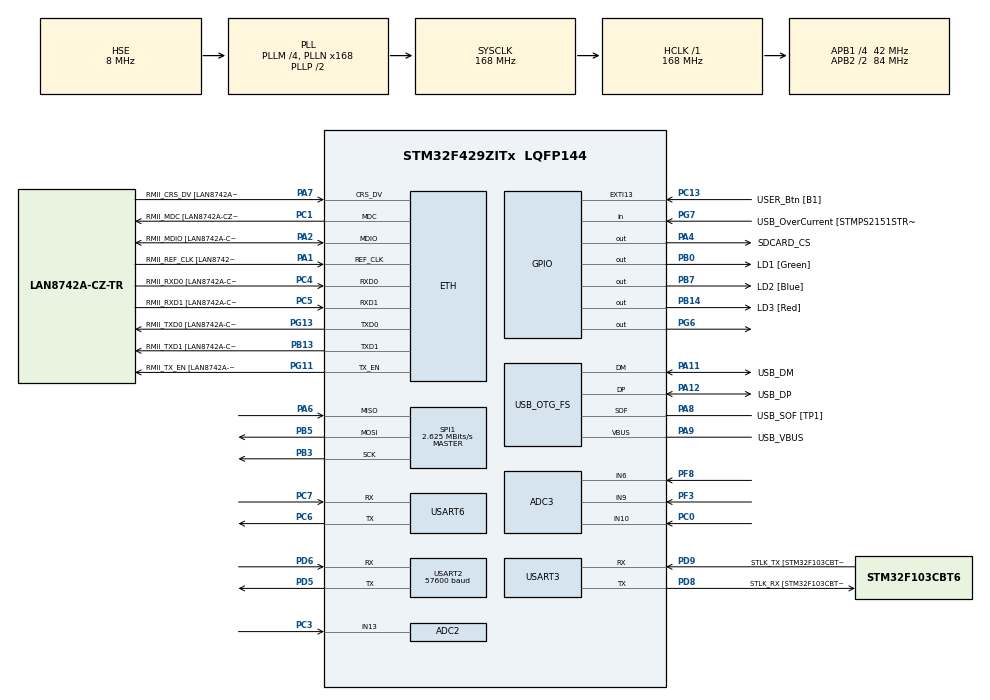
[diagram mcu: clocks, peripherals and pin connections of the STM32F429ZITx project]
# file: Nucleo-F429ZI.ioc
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ADC2.Channel-0\#ChannelRegularConversion=ADC_CHANNEL_13
ADC2.ContinuousConvMode=ENABLE
ADC2.NbrOfConversionFlag=1
ADC2.Rank-0\#ChannelRegularConversion=1
ADC2.SamplingTime-0\#ChannelRegularConversion=ADC_SAMPLETIME_3CYCLES
ADC3.Channel-0\#ChannelRegularConversion=ADC_CHANNEL_6
ADC3.ContinuousConvMode=ENABLE
ADC3.NbrOfConversionFlag=1
ADC3.Rank-0\#ChannelRegularConversion=1
ADC3.SamplingTime-0\#ChannelRegularConversion=ADC_SAMPLETIME_3CYCLES
Dma.Request0=USART2_RX
Dma.Request1=USART2_TX
Dma.Request2=USART3_RX
Dma.Request3=USART3_TX
Dma.USART2_RX.0.Direction=DMA_PERIPH_TO_MEMORY
Dma.USART2_RX.0.FIFOMode=DMA_FIFOMODE_DISABLE
Dma.USART2_RX.0.Instance=DMA1_Stream5
Dma.USART2_RX.0.MemDataAlignment=DMA_MDATAALIGN_BYTE
Dma.USART2_RX.0.MemInc=DMA_MINC_ENABLE
Dma.USART2_RX.0.Mode=DMA_NORMAL
Dma.USART2_RX.0.PeriphDataAlignment=DMA_PDATAALIGN_BYTE
Dma.USART2_RX.0.PeriphInc=DMA_PINC_DISABLE
Dma.USART2_RX.0.Priority=DMA_PRIORITY_LOW
Dma.USART2_TX.1.Direction=DMA_MEMORY_TO_PERIPH
Dma.USART2_TX.1.FIFOMode=DMA_FIFOMODE_DISABLE
Dma.USART2_TX.1.Instance=DMA1_Stream6
Dma.USART2_TX.1.MemDataAlignment=DMA_MDATAALIGN_BYTE
Dma.USART2_TX.1.MemInc=DMA_MINC_ENABLE
Dma.USART2_TX.1.Mode=DMA_CIRCULAR
Dma.USART2_TX.1.PeriphDataAlignment=DMA_PDATAALIGN_BYTE
Dma.USART2_TX.1.PeriphInc=DMA_PINC_DISABLE
Dma.USART2_TX.1.Priority=DMA_PRIORITY_LOW
Dma.USART3_RX.2.Direction=DMA_PERIPH_TO_MEMORY
Dma.USART3_RX.2.FIFOMode=DMA_FIFOMODE_DISABLE
Dma.USART3_RX.2.Instance=DMA1_Stream1
Dma.USART3_RX.2.MemDataAlignment=DMA_MDATAALIGN_BYTE
Dma.USART3_RX.2.MemInc=DMA_MINC_ENABLE
Dma.USART3_RX.2.Mode=DMA_CIRCULAR
Dma.USART3_RX.2.PeriphDataAlignment=DMA_PDATAALIGN_BYTE
Dma.USART3_RX.2.PeriphInc=DMA_PINC_DISABLE
Dma.USART3_RX.2.Priority=DMA_PRIORITY_LOW
Dma.USART3_TX.3.Direction=DMA_MEMORY_TO_PERIPH
Dma.USART3_TX.3.FIFOMode=DMA_FIFOMODE_DISABLE
Dma.USART3_TX.3.Instance=DMA1_Stream3
Dma.USART3_TX.3.MemDataAlignment=DMA_MDATAALIGN_BYTE
Dma.USART3_TX.3.MemInc=DMA_MINC_ENABLE
Dma.USART3_TX.3.Mode=DMA_NORMAL
Dma.USART3_TX.3.PeriphDataAlignment=DMA_PDATAALIGN_BYTE
Dma.USART3_TX.3.PeriphInc=DMA_PINC_DISABLE
Dma.USART3_TX.3.Priority=DMA_PRIORITY_LOW
ETH.MediaInterface=HAL_ETH_RMII_MODE
ETH.PHY_Name=LAN8742A_PHY_ADDRESS
ETH.PHY_Value=0
ETH.PhyAddress=0
FATFS._MAX_SS=4096
FATFS._USE_LFN=1
Mcu.Family=STM32F4
Mcu.Name=STM32F429ZITx
Mcu.Package=LQFP144
NVIC.ADC_IRQn=true\:6\:0\:true\:false\:true\:true\:true\:true
NVIC.DMA1_Stream1_IRQn=true\:0\:0\:false\:false\:true\:false\:true\:true
NVIC.DMA1_Stream3_IRQn=true\:0\:0\:false\:false\:true\:false\:true\:true
NVIC.DMA1_Stream5_IRQn=true\:0\:0\:false\:false\:true\:false\:true\:true
NVIC.DMA1_Stream6_IRQn=true\:0\:0\:false\:false\:true\:false\:true\:true
NVIC.PriorityGroup=NVIC_PRIORITYGROUP_4
NVIC.TIM1_UP_TIM10_IRQn=true\:15\:0\:true\:false\:true\:false\:true\:true
NVIC.TimeBase=TIM1_UP_TIM10_IRQn
NVIC.TimeBaseIP=TIM1
NVIC.USART2_IRQn=true\:5\:0\:true\:false\:true\:true\:true\:true
NVIC.USART3_IRQn=true\:5\:0\:true\:false\:true\:true\:true\:true
NVIC.USART6_IRQn=true\:5\:0\:true\:false\:true\:true\:true\:true
PA1.GPIO_Label=RMII_REF_CLK [LAN8742A-CZ-TR_REFCLK0]
PA1.Mode=RMII
PA1.Signal=ETH_REF_CLK
PA10.GPIO_Label=USB_ID
PA10.Signal=USB_OTG_FS_ID
PA11.GPIO_Label=USB_DM
PA11.Mode=Device_Only
PA11.Signal=USB_OTG_FS_DM
PA12.GPIO_Label=USB_DP
PA12.Mode=Device_Only
PA12.Signal=USB_OTG_FS_DP
PA13.GPIO_Label=TMS
PA13.Mode=Serial_Wire
PA13.Signal=SYS_JTMS-SWDIO
PA14.GPIO_Label=TCK
PA14.Mode=Serial_Wire
PA14.Signal=SYS_JTCK-SWCLK
PA2.GPIO_Label=RMII_MDIO [LAN8742A-CZ-TR_MDIO]
PA2.Mode=RMII
PA2.Signal=ETH_MDIO
PA4.GPIO_Label=SDCARD_CS
PA4.PinState=GPIO_PIN_SET
PA4.Signal=GPIO_Output
PA6.Mode=Full_Duplex_Master
PA6.Signal=SPI1_MISO
PA7.GPIO_Label=RMII_CRS_DV [LAN8742A-CZ-TR_CRS_DV]
PA7.Mode=RMII
PA7.Signal=ETH_CRS_DV
PA8.GPIO_Label=USB_SOF [TP1]
PA8.Mode=Activate_SOF_FS
PA8.Signal=USB_OTG_FS_SOF
PA9.GPIO_Label=USB_VBUS
PA9.Mode=Activate_VBUS
PA9.Signal=USB_OTG_FS_VBUS
PB0.GPIO_Label=LD1 [Green]
PB0.Signal=GPIO_Output
PB13.GPIO_Label=RMII_TXD1 [LAN8742A-CZ-TR_TXD1]
PB13.Mode=RMII
PB13.Signal=ETH_TXD1
PB14.GPIO_Label=LD3 [Red]
PB14.Signal=GPIO_Output
PB3.Mode=Full_Duplex_Master
PB3.Signal=SPI1_SCK
PB5.Mode=Full_Duplex_Master
PB5.Signal=SPI1_MOSI
PB7.GPIO_Label=LD2 [Blue]
PB7.Signal=GPIO_Output
PC0.Signal=ADCx_IN10
PC1.GPIO_Label=RMII_MDC [LAN8742A-CZ-TR_MDC]
PC1.Mode=RMII
PC1.Signal=ETH_MDC
PC13.GPIO_Label=USER_Btn [B1]
PC13.Signal=GPXTI13
PC14/OSC32_IN.Mode=LSE-External-Oscillator
PC14/OSC32_IN.Signal=RCC_OSC32_IN
PC15/OSC32_OUT.Mode=LSE-External-Oscillator
PC15/OSC32_OUT.Signal=RCC_OSC32_OUT
PC3.Signal=ADCx_IN13
PC4.GPIO_Label=RMII_RXD0 [LAN8742A-CZ-TR_RXD0]
PC4.Mode=RMII
PC4.Signal=ETH_RXD0
PC5.GPIO_Label=RMII_RXD1 [LAN8742A-CZ-TR_RXD1]
PC5.Mode=RMII
PC5.Signal=ETH_RXD1
PC6.Mode=Asynchronous
PC6.Signal=USART6_TX
PC7.Mode=Asynchronous
PC7.Signal=USART6_RX
PD5.Mode=Asynchronous
PD5.Signal=USART2_TX
PD6.Mode=Asynchronous
PD6.Signal=USART2_RX
PD8.GPIO_Label=STLK_RX [STM32F103CBT6_PA3]
PD8.Mode=Asynchronous
PD8.Signal=USART3_TX
PD9.GPIO_Label=STLK_TX [STM32F103CBT6_PA2]
PD9.Mode=Asynchronous
PD9.Signal=USART3_RX
PF3.Mode=IN9
PF3.Signal=ADC3_IN9
PF8.Mode=IN6
PF8.Signal=ADC3_IN6
PG11.GPIO_Label=RMII_TX_EN [LAN8742A-CZ-TR_TXEN]
PG11.Mode=RMII
PG11.Signal=ETH_TX_EN
PG13.GPIO_Label=RMII_TXD0 [LAN8742A-CZ-TR_TXD0]
PG13.Mode=RMII
PG13.Signal=ETH_TXD0
PG6.Signal=GPIO_Output
PG7.GPIO_Label=USB_OverCurrent [STMPS2151STR_FAULT]
PG7.Signal=GPIO_Input
PH0/OSC_IN.GPIO_Label=MCO [STM32F103CBT6_PA8]
PH0/OSC_IN.Mode=HSE-External-Clock-Source
PH0/OSC_IN.Signal=RCC_OSC_IN
PH1/OSC_OUT.Mode=HSE-External-Clock-Source
PH1/OSC_OUT.Signal=RCC_OSC_OUT
ProjectManager.HeapSize=0x200
ProjectManager.StackSize=0x400
ProjectManager.TargetToolchain=Makefile
RCC.48MHZClocksFreq_Value=48000000
RCC.AHBFreq_Value=168000000
RCC.APB1CLKDivider=RCC_HCLK_DIV4
RCC.APB1Freq_Value=42000000
RCC.APB1TimFreq_Value=84000000
RCC.APB2CLKDivider=RCC_HCLK_DIV2
RCC.APB2Freq_Value=84000000
RCC.APB2TimCLKDivider=2
RCC.APB2TimFreq_Value=168000000
RCC.CortexFreq_Value=168000000
RCC.HCLKFreq_Value=168000000
RCC.HSE_VALUE=8000000
RCC.HSI_VALUE=16000000
RCC.PLLM=4
RCC.PLLMUL=RCC_PLL_MUL9
RCC.PLLN=168
RCC.PLLQ=7
RCC.PRESCALERUSB=RCC_USBCLKSOURCE_PLL_DIV1_5
RCC.SYSCLKFreq_VALUE=168000000
RCC.SYSCLKSource=RCC_SYSCLKSOURCE_PLLCLK
RCC.SYSCLKSourceVirtual=RCC_SYSCLKSOURCE_PLLCLK
RCC.USBFreq_Value=48000000
RCC.VCOOutputFreq_Value=336000000
SH.ADCx_IN10.0=ADC3_IN10,IN10
SH.ADCx_IN13.0=ADC2_IN13,IN13
SPI1.BaudRatePrescaler=SPI_BAUDRATEPRESCALER_32
SPI1.CalculateBaudRate=2.625 MBits/s
SPI1.Direction=SPI_DIRECTION_2LINES
SPI1.Mode=SPI_MODE_MASTER
SPI1.VirtualType=VM_MASTER
USART2.BaudRate=57600
USART2.VirtualMode=VM_ASYNC
USART3.VirtualMode=VM_ASYNC
USART6.VirtualMode=VM_ASYNC
USB_OTG_FS.VirtualMode=Device_Only
VP_FATFS_VS_Generic.Mode=User_defined
VP_SYS_VS_tim1.Mode=TIM1
board=NUCLEO-F429ZI

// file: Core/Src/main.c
/* USER CODE BEGIN Header */
/**
  ******************************************************************************
  * @file           : main.c
  * @brief          : Main program body
  ******************************************************************************
  * @attention
  *
  * Copyright (c) 2024 STMicroelectronics.
  * All rights reserved.
  *
  * This software is licensed under terms that can be found in the LICENSE file
  * in the root directory of this software component.
  * If no LICENSE file comes with this software, it is provided AS-IS.
  *
  ******************************************************************************
  */
/* USER CODE END Header */
#include "main.h"
#include "string.h"
#include "fatfs.h"

/* USER CODE BEGIN Includes */
#include "port_layer.h"
/* USER CODE END Includes */

ETH_TxPacketConfig TxConfig;
ETH_DMADescTypeDef  DMARxDscrTab[ETH_RX_DESC_CNT]; /* Ethernet Rx DMA Descriptors */
ETH_DMADescTypeDef  DMATxDscrTab[ETH_TX_DESC_CNT]; /* Ethernet Tx DMA Descriptors */

ADC_HandleTypeDef hadc2;
ADC_HandleTypeDef hadc3;

ETH_HandleTypeDef heth;

SPI_HandleTypeDef hspi1;

UART_HandleTypeDef huart2;
UART_HandleTypeDef huart3;
UART_HandleTypeDef huart6;
DMA_HandleTypeDef hdma_usart2_rx;
DMA_HandleTypeDef hdma_usart2_tx;
DMA_HandleTypeDef hdma_usart3_rx;
DMA_HandleTypeDef hdma_usart3_tx;

PCD_HandleTypeDef hpcd_USB_OTG_FS;

void SystemClock_Config(void);
static void MX_GPIO_Init(void);
static void MX_DMA_Init(void);
static void MX_ETH_Init(void);
static void MX_SPI1_Init(void);
static void MX_USART2_UART_Init(void);
static void MX_USART3_UART_Init(void);
static void MX_USB_OTG_FS_PCD_Init(void);
static void MX_USART6_UART_Init(void);
static void MX_ADC2_Init(void);
static void MX_ADC3_Init(void);

/* USER CODE BEGIN 0 */
uint8_t n_bytes = 0;
uint8_t rx_buf[16];
/* USER CODE END 0 */

int main(void)
{

  /* MCU Configuration--------------------------------------------------------*/

  /* Reset of all peripherals, Initializes the Flash interface and the Systick. */
  HAL_Init();

  /* Configure the system clock */
  SystemClock_Config();

  /* Initialize all configured peripherals */
  MX_GPIO_Init();
  MX_DMA_Init();
  MX_ETH_Init();
  MX_SPI1_Init();
  MX_USART2_UART_Init();
  MX_USART3_UART_Init();
  MX_USB_OTG_FS_PCD_Init();
  MX_FATFS_Init();
  MX_USART6_UART_Init();
  MX_ADC2_Init();
  MX_ADC3_Init();
  /* USER CODE BEGIN 2 */
  if (port_init()) {
    HAL_UART_Transmit(&debug_uart, (uint8_t *) "Port init successful\r\n", 22, HAL_MAX_DELAY);
  } else {
    HAL_UART_Transmit(&debug_uart, (uint8_t *) "Port init failed\r\n", 18, HAL_MAX_DELAY);
  }
  port_start();
  /* USER CODE END 2 */

  /* Infinite loop */
  while (1)
  {

  }
}

void SystemClock_Config(void)
{
  RCC_OscInitTypeDef RCC_OscInitStruct = {0};
  RCC_ClkInitTypeDef RCC_ClkInitStruct = {0};

  /** Configure the main internal regulator output voltage
  */
  __HAL_RCC_PWR_CLK_ENABLE();
  __HAL_PWR_VOLTAGESCALING_CONFIG(PWR_REGULATOR_VOLTAGE_SCALE1);

  /** Initializes the RCC Oscillators according to the specified parameters
  * in the RCC_OscInitTypeDef structure.
  */
  RCC_OscInitStruct.OscillatorType = RCC_OSCILLATORTYPE_HSE;
  RCC_OscInitStruct.HSEState = RCC_HSE_BYPASS;
  RCC_OscInitStruct.PLL.PLLState = RCC_PLL_ON;
  RCC_OscInitStruct.PLL.PLLSource = RCC_PLLSOURCE_HSE;
  RCC_OscInitStruct.PLL.PLLM = 4;
  RCC_OscInitStruct.PLL.PLLN = 168;
  RCC_OscInitStruct.PLL.PLLP = RCC_PLLP_DIV2;
  RCC_OscInitStruct.PLL.PLLQ = 7;
  if (HAL_RCC_OscConfig(&RCC_OscInitStruct) != HAL_OK)
  {
    Error_Handler();
  }

  /** Initializes the CPU, AHB and APB buses clocks
  */
  RCC_ClkInitStruct.ClockType = RCC_CLOCKTYPE_HCLK|RCC_CLOCKTYPE_SYSCLK
                              |RCC_CLOCKTYPE_PCLK1|RCC_CLOCKTYPE_PCLK2;
  RCC_ClkInitStruct.SYSCLKSource = RCC_SYSCLKSOURCE_PLLCLK;
  RCC_ClkInitStruct.AHBCLKDivider = RCC_SYSCLK_DIV1;
  RCC_ClkInitStruct.APB1CLKDivider = RCC_HCLK_DIV4;
  RCC_ClkInitStruct.APB2CLKDivider = RCC_HCLK_DIV2;

  if (HAL_RCC_ClockConfig(&RCC_ClkInitStruct, FLASH_LATENCY_5) != HAL_OK)
  {
    Error_Handler();
  }
}

static void MX_ADC2_Init(void)
{

  ADC_ChannelConfTypeDef sConfig = {0};

  /** Configure the global features of the ADC (Clock, Resolution, Data Alignment and number of conversion)
  */
  hadc2.Instance = ADC2;
  hadc2.Init.ClockPrescaler = ADC_CLOCK_SYNC_PCLK_DIV4;
  hadc2.Init.Resolution = ADC_RESOLUTION_12B;
  hadc2.Init.ScanConvMode = DISABLE;
  hadc2.Init.ContinuousConvMode = ENABLE;
  hadc2.Init.DiscontinuousConvMode = DISABLE;
  hadc2.Init.ExternalTrigConvEdge = ADC_EXTERNALTRIGCONVEDGE_NONE;
  hadc2.Init.ExternalTrigConv = ADC_SOFTWARE_START;
  hadc2.Init.DataAlign = ADC_DATAALIGN_RIGHT;
  hadc2.Init.NbrOfConversion = 1;
  hadc2.Init.DMAContinuousRequests = DISABLE;
  hadc2.Init.EOCSelection = ADC_EOC_SINGLE_CONV;
  if (HAL_ADC_Init(&hadc2) != HAL_OK)
  {
    Error_Handler();
  }

  /** Configure for the selected ADC regular channel its corresponding rank in the sequencer and its sample time.
  */
  sConfig.Channel = ADC_CHANNEL_13;
  sConfig.Rank = 1;
  sConfig.SamplingTime = ADC_SAMPLETIME_3CYCLES;
  if (HAL_ADC_ConfigChannel(&hadc2, &sConfig) != HAL_OK)
  {
    Error_Handler();
  }

}

static void MX_ADC3_Init(void)
{

  ADC_ChannelConfTypeDef sConfig = {0};

  /** Configure the global features of the ADC (Clock, Resolution, Data Alignment and number of conversion)
  */
  hadc3.Instance = ADC3;
  hadc3.Init.ClockPrescaler = ADC_CLOCK_SYNC_PCLK_DIV4;
  hadc3.Init.Resolution = ADC_RESOLUTION_12B;
  hadc3.Init.ScanConvMode = DISABLE;
  hadc3.Init.ContinuousConvMode = ENABLE;
  hadc3.Init.DiscontinuousConvMode = DISABLE;
  hadc3.Init.ExternalTrigConvEdge = ADC_EXTERNALTRIGCONVEDGE_NONE;
  hadc3.Init.ExternalTrigConv = ADC_SOFTWARE_START;
  hadc3.Init.DataAlign = ADC_DATAALIGN_RIGHT;
  hadc3.Init.NbrOfConversion = 1;
  hadc3.Init.DMAContinuousRequests = DISABLE;
  hadc3.Init.EOCSelection = ADC_EOC_SINGLE_CONV;
  if (HAL_ADC_Init(&hadc3) != HAL_OK)
  {
    Error_Handler();
  }

  /** Configure for the selected ADC regular channel its corresponding rank in the sequencer and its sample time.
  */
  sConfig.Channel = ADC_CHANNEL_6;
  sConfig.Rank = 1;
  sConfig.SamplingTime = ADC_SAMPLETIME_3CYCLES;
  if (HAL_ADC_ConfigChannel(&hadc3, &sConfig) != HAL_OK)
  {
    Error_Handler();
  }

}

static void MX_ETH_Init(void)
{

   static uint8_t MACAddr[6];

  heth.Instance = ETH;
  MACAddr[0] = 0x00;
  MACAddr[1] = 0x80;
  MACAddr[2] = 0xE1;
  MACAddr[3] = 0x00;
  MACAddr[4] = 0x00;
  MACAddr[5] = 0x00;
  heth.Init.MACAddr = &MACAddr[0];
  heth.Init.MediaInterface = HAL_ETH_RMII_MODE;
  heth.Init.TxDesc = DMATxDscrTab;
  heth.Init.RxDesc = DMARxDscrTab;
  heth.Init.RxBuffLen = 1524;

  if (HAL_ETH_Init(&heth) != HAL_OK)
  {
    Error_Handler();
  }

  memset(&TxConfig, 0 , sizeof(ETH_TxPacketConfig));
  TxConfig.Attributes = ETH_TX_PACKETS_FEATURES_CSUM | ETH_TX_PACKETS_FEATURES_CRCPAD;
  TxConfig.ChecksumCtrl = ETH_CHECKSUM_IPHDR_PAYLOAD_INSERT_PHDR_CALC;
  TxConfig.CRCPadCtrl = ETH_CRC_PAD_INSERT;

}

static void MX_SPI1_Init(void)
{

  /* SPI1 parameter configuration*/
  hspi1.Instance = SPI1;
  hspi1.Init.Mode = SPI_MODE_MASTER;
  hspi1.Init.Direction = SPI_DIRECTION_2LINES;
  hspi1.Init.DataSize = SPI_DATASIZE_8BIT;
  hspi1.Init.CLKPolarity = SPI_POLARITY_LOW;
  hspi1.Init.CLKPhase = SPI_PHASE_1EDGE;
  hspi1.Init.NSS = SPI_NSS_SOFT;
  hspi1.Init.BaudRatePrescaler = SPI_BAUDRATEPRESCALER_32;
  hspi1.Init.FirstBit = SPI_FIRSTBIT_MSB;
  hspi1.Init.TIMode = SPI_TIMODE_DISABLE;
  hspi1.Init.CRCCalculation = SPI_CRCCALCULATION_DISABLE;
  hspi1.Init.CRCPolynomial = 10;
  if (HAL_SPI_Init(&hspi1) != HAL_OK)
  {
    Error_Handler();
  }

}

static void MX_USART2_UART_Init(void)
{

  huart2.Instance = USART2;
  huart2.Init.BaudRate = 57600;
  huart2.Init.WordLength = UART_WORDLENGTH_8B;
  huart2.Init.StopBits = UART_STOPBITS_1;
  huart2.Init.Parity = UART_PARITY_NONE;
  huart2.Init.Mode = UART_MODE_TX_RX;
  huart2.Init.HwFlowCtl = UART_HWCONTROL_NONE;
  huart2.Init.OverSampling = UART_OVERSAMPLING_16;
  if (HAL_UART_Init(&huart2) != HAL_OK)
  {
    Error_Handler();
  }

}

static void MX_USART3_UART_Init(void)
{

  huart3.Instance = USART3;
  huart3.Init.BaudRate = 115200;
  huart3.Init.WordLength = UART_WORDLENGTH_8B;
  huart3.Init.StopBits = UART_STOPBITS_1;
  huart3.Init.Parity = UART_PARITY_NONE;
  huart3.Init.Mode = UART_MODE_TX_RX;
  huart3.Init.HwFlowCtl = UART_HWCONTROL_NONE;
  huart3.Init.OverSampling = UART_OVERSAMPLING_16;
  if (HAL_UART_Init(&huart3) != HAL_OK)
  {
    Error_Handler();
  }

}

static void MX_USART6_UART_Init(void)
{

  huart6.Instance = USART6;
  huart6.Init.BaudRate = 115200;
  huart6.Init.WordLength = UART_WORDLENGTH_8B;
  huart6.Init.StopBits = UART_STOPBITS_1;
  huart6.Init.Parity = UART_PARITY_NONE;
  huart6.Init.Mode = UART_MODE_TX_RX;
  huart6.Init.HwFlowCtl = UART_HWCONTROL_NONE;
  huart6.Init.OverSampling = UART_OVERSAMPLING_16;
  if (HAL_UART_Init(&huart6) != HAL_OK)
  {
    Error_Handler();
  }

}

static void MX_USB_OTG_FS_PCD_Init(void)
{

  hpcd_USB_OTG_FS.Instance = USB_OTG_FS;
  hpcd_USB_OTG_FS.Init.dev_endpoints = 4;
  hpcd_USB_OTG_FS.Init.speed = PCD_SPEED_FULL;
  hpcd_USB_OTG_FS.Init.dma_enable = DISABLE;
  hpcd_USB_OTG_FS.Init.phy_itface = PCD_PHY_EMBEDDED;
  hpcd_USB_OTG_FS.Init.Sof_enable = ENABLE;
  hpcd_USB_OTG_FS.Init.low_power_enable = DISABLE;
  hpcd_USB_OTG_FS.Init.lpm_enable = DISABLE;
  hpcd_USB_OTG_FS.Init.vbus_sensing_enable = ENABLE;
  hpcd_USB_OTG_FS.Init.use_dedicated_ep1 = DISABLE;
  if (HAL_PCD_Init(&hpcd_USB_OTG_FS) != HAL_OK)
  {
    Error_Handler();
  }

}

static void MX_DMA_Init(void)
{

  /* DMA controller clock enable */
  __HAL_RCC_DMA1_CLK_ENABLE();

  /* DMA interrupt init */
  /* DMA1_Stream1_IRQn interrupt configuration */
  HAL_NVIC_SetPriority(DMA1_Stream1_IRQn, 0, 0);
  HAL_NVIC_EnableIRQ(DMA1_Stream1_IRQn);
  /* DMA1_Stream3_IRQn interrupt configuration */
  HAL_NVIC_SetPriority(DMA1_Stream3_IRQn, 0, 0);
  HAL_NVIC_EnableIRQ(DMA1_Stream3_IRQn);
  /* DMA1_Stream5_IRQn interrupt configuration */
  HAL_NVIC_SetPriority(DMA1_Stream5_IRQn, 0, 0);
  HAL_NVIC_EnableIRQ(DMA1_Stream5_IRQn);
  /* DMA1_Stream6_IRQn interrupt configuration */
  HAL_NVIC_SetPriority(DMA1_Stream6_IRQn, 0, 0);
  HAL_NVIC_EnableIRQ(DMA1_Stream6_IRQn);

}

static void MX_GPIO_Init(void)
{
  GPIO_InitTypeDef GPIO_InitStruct = {0};

  /* GPIO Ports Clock Enable */
  __HAL_RCC_GPIOC_CLK_ENABLE();
  __HAL_RCC_GPIOF_CLK_ENABLE();
  __HAL_RCC_GPIOH_CLK_ENABLE();
  __HAL_RCC_GPIOA_CLK_ENABLE();
  __HAL_RCC_GPIOB_CLK_ENABLE();
  __HAL_RCC_GPIOD_CLK_ENABLE();
  __HAL_RCC_GPIOG_CLK_ENABLE();

  /*Configure GPIO pin Output Level */
  HAL_GPIO_WritePin(SDCARD_CS_GPIO_Port, SDCARD_CS_Pin, GPIO_PIN_SET);

  /*Configure GPIO pin Output Level */
  HAL_GPIO_WritePin(GPIOB, LD1_Pin|LD3_Pin|LD2_Pin, GPIO_PIN_RESET);

  /*Configure GPIO pin Output Level */
  HAL_GPIO_WritePin(GPIOG, GPIO_PIN_6, GPIO_PIN_RESET);

  /*Configure GPIO pin : USER_Btn_Pin */
  GPIO_InitStruct.Pin = USER_Btn_Pin;
  GPIO_InitStruct.Mode = GPIO_MODE_IT_RISING;
  GPIO_InitStruct.Pull = GPIO_NOPULL;
  HAL_GPIO_Init(USER_Btn_GPIO_Port, &GPIO_InitStruct);

  /*Configure GPIO pin : SDCARD_CS_Pin */
  GPIO_InitStruct.Pin = SDCARD_CS_Pin;
  GPIO_InitStruct.Mode = GPIO_MODE_OUTPUT_PP;
  GPIO_InitStruct.Pull = GPIO_NOPULL;
  GPIO_InitStruct.Speed = GPIO_SPEED_FREQ_LOW;
  HAL_GPIO_Init(SDCARD_CS_GPIO_Port, &GPIO_InitStruct);

  /*Configure GPIO pins : LD1_Pin LD3_Pin LD2_Pin */
  GPIO_InitStruct.Pin = LD1_Pin|LD3_Pin|LD2_Pin;
  GPIO_InitStruct.Mode = GPIO_MODE_OUTPUT_PP;
  GPIO_InitStruct.Pull = GPIO_NOPULL;
  GPIO_InitStruct.Speed = GPIO_SPEED_FREQ_LOW;
  HAL_GPIO_Init(GPIOB, &GPIO_InitStruct);

  /*Configure GPIO pin : PG6 */
  GPIO_InitStruct.Pin = GPIO_PIN_6;
  GPIO_InitStruct.Mode = GPIO_MODE_OUTPUT_PP;
  GPIO_InitStruct.Pull = GPIO_NOPULL;
  GPIO_InitStruct.Speed = GPIO_SPEED_FREQ_LOW;
  HAL_GPIO_Init(GPIOG, &GPIO_InitStruct);

  /*Configure GPIO pin : USB_OverCurrent_Pin */
  GPIO_InitStruct.Pin = USB_OverCurrent_Pin;
  GPIO_InitStruct.Mode = GPIO_MODE_INPUT;
  GPIO_InitStruct.Pull = GPIO_NOPULL;
  HAL_GPIO_Init(USB_OverCurrent_GPIO_Port, &GPIO_InitStruct);

}

void HAL_TIM_PeriodElapsedCallback(TIM_HandleTypeDef *htim)
{
  if (htim->Instance == TIM1) {
    HAL_IncTick();
  }
}

void Error_Handler(void)
{
  __disable_irq();
  while (1)
  {
  }
}
